# renode register map
Vendor: litex
Registers are 32-bit, read-write, reset 0x0 unless marked. A register's access mark holds for its fields unless they carry their own. Offsets are from the block's base; [hi:lo] are bit positions.

## COM
Base 0xF000C000
0x00 TX — Tx data, for COPI. Note: 32-bit CSRs are required for this block to work!
  [15:0] tx
0x04 RX — Rx data, from CIPO
  [15:0] rx
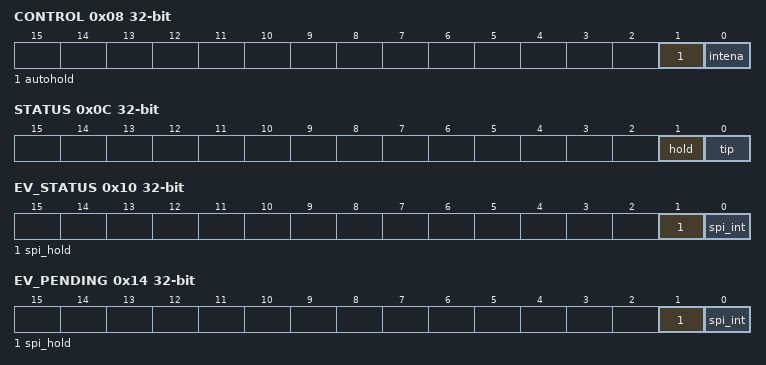
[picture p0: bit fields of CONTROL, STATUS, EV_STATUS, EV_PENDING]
0x08 CONTROL
  [1] autohold — Disallow transmission start if hold if asserted
  [0] intena — Enable interrupt on transaction finished
0x0C STATUS
  [1] hold — Set when peripheral asserts hold
  [0] tip — Set when transaction is in progress
0x10 EV_STATUS — This register contains the current raw level of the spi_hold event trigger. Writes to this register have no effect.
  [1] spi_hold — Level of the ``spi_hold`` event
  [0] spi_int — Level of the ``spi_int`` event
0x14 EV_PENDING — When a spi_hold event occurs, the corresponding bit will be set in this register. To clear the Event, set the corresponding bit in this register.
  [1] spi_hold — `1` if a `spi_hold` event occurred. This Event is triggered on a **falling** edge.
  [0] spi_int — `1` if a `spi_int` event occurred. This Event is triggered on a **falling** edge.
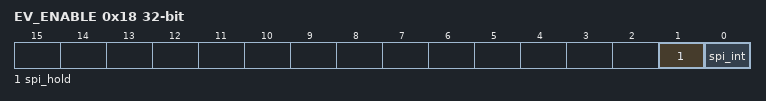
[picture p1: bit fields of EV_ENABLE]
0x18 EV_ENABLE — This register enables the corresponding spi_hold events. Write a ``0`` to this register to disable individual events.
  [1] spi_hold — Write a ``1`` to enable the ``spi_hold`` Event
  [0] spi_int — Write a ``1`` to enable the ``spi_int`` Event

## I2C
Base 0xF000D000
0x00 PRESCALE reset 0xFFFF — Prescaler value. Set to (module clock / (5 * I2C freq) - 1). Example: if module clock is equal to sysclk; syclk is 100MHz; and I2C freq is 100kHz, then prescaler is (100MHz / (5 * 100kHz) - 1) = 199. Reset value: 0xFFFF
  [15:0] prescale
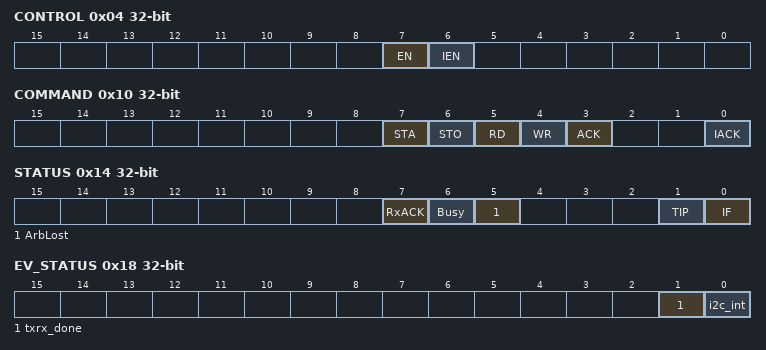
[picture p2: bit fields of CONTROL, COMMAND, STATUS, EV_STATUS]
0x04 CONTROL
  [7] EN — When set to `1`, the core is enabled.
  [6] IEN — When set to `1`, interrupts are enabled.
0x08 TXR — Next byte to transmit to slave devices. LSB indicates R/W during address phases, `1` for reading from slaves, `0` for writing to slaves
  [7:0] txr
0x0C RXR — Data being read from slaved devices
  [7:0] rxr
0x10 COMMAND
  [7] STA — generate (repeated) start condition
  [6] STO — generate stop condition
  [5] RD — read from slave
  [4] WR — write to slave
  [3] ACK — when a receiver, sent ack (`ACK=0`) or nack (`ACK=1`)
  [0] IACK — Interrupt acknowledge; when set, clears a pending interrupt
0x14 STATUS
  [7] RxACK — Received acknowledge from slave. 1 = no ack received, 0 = ack received
  [6] Busy — I2C block is busy processing the latest command
  [5] ArbLost — Set when arbitration for the bus is lost
  [1] TIP — transfer in progress
  [0] IF — Interrupt flag, This bit is set when an interrupt is pending, which will cause a processor interrupt request if the IEN bit is set. The Interrupt Flag is set upon the completion of one byte of data transfer.
0x18 EV_STATUS — Triggered on the falling edge of TIP
  [1] txrx_done — Level of the ``txrx_done`` event
  [0] i2c_int — Level of the ``i2c_int`` event
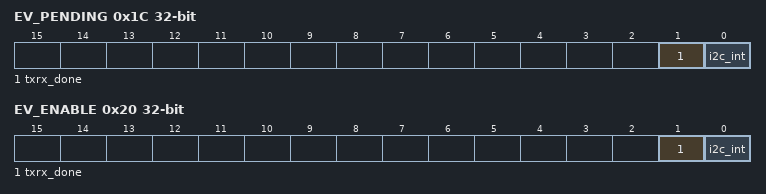
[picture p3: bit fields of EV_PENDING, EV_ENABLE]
0x1C EV_PENDING — Triggered on the falling edge of TIP
  [1] txrx_done — Triggered on the falling edge of TIP
  [0] i2c_int — Triggered when arbitration is lost or transaction done. Requires IACK write to clear or else it will re-trigger.
0x20 EV_ENABLE — Triggered on the falling edge of TIP
  [1] txrx_done — Write a ``1`` to enable the ``txrx_done`` Event
  [0] i2c_int — Write a ``1`` to enable the ``i2c_int`` Event

## BTEVENTS
Base 0xF000E000
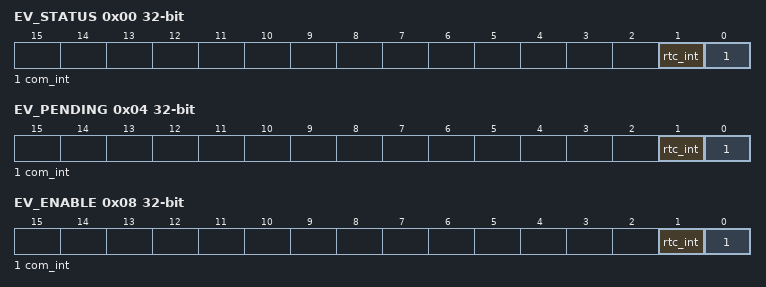
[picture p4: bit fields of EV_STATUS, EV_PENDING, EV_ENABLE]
0x00 EV_STATUS — This register contains the current raw level of the rtc_int event trigger. Writes to this register have no effect.
  [1] rtc_int — Level of the ``rtc_int`` event
  [0] com_int — Level of the ``com_int`` event
0x04 EV_PENDING — When a rtc_int event occurs, the corresponding bit will be set in this register. To clear the Event, set the corresponding bit in this register.
  [1] rtc_int — `1` if a `rtc_int` event occurred. This Event is triggered on a **falling** edge.
  [0] com_int — `1` if a `com_int` event occurred. This Event is triggered on a **rising** edge.
0x08 EV_ENABLE — This register enables the corresponding rtc_int events. Write a ``0`` to this register to disable individual events.
  [1] rtc_int — Write a ``1`` to enable the ``rtc_int`` Event
  [0] com_int — Write a ``1`` to enable the ``com_int`` Event
